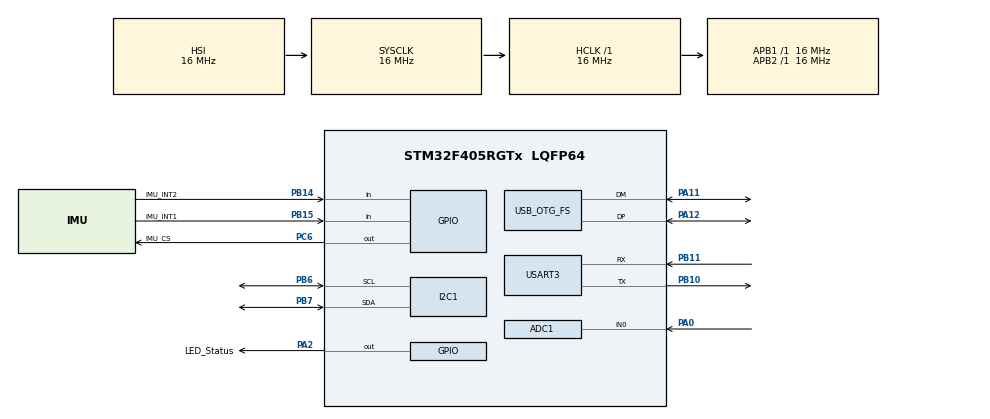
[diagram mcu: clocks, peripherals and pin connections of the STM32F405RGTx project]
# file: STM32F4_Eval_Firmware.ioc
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ADC1.Channel-0\#ChannelRegularConversion=ADC_CHANNEL_0
ADC1.NbrOfConversionFlag=1
ADC1.Rank-0\#ChannelRegularConversion=1
ADC1.SamplingTime-0\#ChannelRegularConversion=ADC_SAMPLETIME_3CYCLES
ADC1.master=1
Mcu.Family=STM32F4
Mcu.Name=STM32F405RGTx
Mcu.Package=LQFP64
NVIC.OTG_FS_IRQn=true\:0\:0\:false\:false\:true\:false\:true
NVIC.PriorityGroup=NVIC_PRIORITYGROUP_4
NVIC.TIM1_TRG_COM_TIM11_IRQn=true\:0\:0\:false\:false\:true\:true\:true
NVIC.USART3_IRQn=true\:0\:0\:false\:false\:true\:true\:true
PA0-WKUP.Signal=ADCx_IN0
PA11.Mode=Device_Only
PA11.Signal=USB_OTG_FS_DM
PA12.Mode=Device_Only
PA12.Signal=USB_OTG_FS_DP
PA13.Mode=Trace_Asynchronous_SW
PA13.Signal=SYS_JTMS-SWDIO
PA14.Mode=Trace_Asynchronous_SW
PA14.Signal=SYS_JTCK-SWCLK
PA2.GPIO_Label=LED_Status
PA2.Signal=GPIO_Output
PB10.Mode=Asynchronous
PB10.Signal=USART3_TX
PB11.Mode=Asynchronous
PB11.Signal=USART3_RX
PB14.GPIO_Label=IMU_INT2
PB14.Signal=GPIO_Input
PB15.GPIO_Label=IMU_INT1
PB15.Signal=GPIO_Input
PB3.Mode=Trace_Asynchronous_SW
PB3.Signal=SYS_JTDO-SWO
PB6.Mode=I2C
PB6.Signal=I2C1_SCL
PB7.Mode=I2C
PB7.Signal=I2C1_SDA
PC6.GPIO_Label=IMU_CS
PC6.Signal=GPIO_Output
PH0-OSC_IN.Mode=HSE-External-Oscillator
PH0-OSC_IN.Signal=RCC_OSC_IN
PH1-OSC_OUT.Mode=HSE-External-Oscillator
PH1-OSC_OUT.Signal=RCC_OSC_OUT
ProjectManager.HeapSize=0x200
ProjectManager.StackSize=0x400
ProjectManager.TargetToolchain=STM32CubeIDE
RCC.48MHZClocksFreq_Value=48000000
RCC.AHBFreq_Value=16000000
RCC.APB1Freq_Value=16000000
RCC.APB1TimFreq_Value=16000000
RCC.APB2Freq_Value=16000000
RCC.APB2TimFreq_Value=16000000
RCC.CortexFreq_Value=16000000
RCC.HCLKFreq_Value=16000000
RCC.HSE_VALUE=25000000
RCC.HSI_VALUE=16000000
RCC.LSE_VALUE=32768
RCC.PLLM=15
RCC.PLLN=144
RCC.PLLQ=5
RCC.SYSCLKFreq_VALUE=16000000
RCC.VCOOutputFreq_Value=240000000
SH.ADCx_IN0.0=ADC1_IN0,IN0
TIM11.Period=15850
TIM11.Prescaler=0
USART3.VirtualMode=VM_ASYNC
USB_DEVICE.CLASS_NAME_FS=CDC
USB_DEVICE.VirtualMode-CDC_FS=Cdc
USB_DEVICE.VirtualModeFS=Cdc_FS
USB_OTG_FS.VirtualMode=Device_Only
VP_TIM11_VS_ClockSourceINT.Mode=Enable_Timer
VP_USB_DEVICE_VS_USB_DEVICE_CDC_FS.Mode=CDC_FS
board=custom

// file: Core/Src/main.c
/* USER CODE BEGIN Header */
/**
  ******************************************************************************
  * @file           : main.c
  * @brief          : Main program body
  ******************************************************************************
  * @attention
  *
  * <h2><center>&copy; Copyright (c) 2020 STMicroelectronics.
  * All rights reserved.</center></h2>
  *
  * This software component is licensed by ST under BSD 3-Clause license,
  * the "License"; You may not use this file except in compliance with the
  * License. You may obtain a copy of the License at:
  *                        opensource.org/licenses/BSD-3-Clause
  *
  ******************************************************************************
  */
/* USER CODE END Header */
#include "main.h"
#include "usb_device.h"

ADC_HandleTypeDef hadc1;

I2C_HandleTypeDef hi2c1;

TIM_HandleTypeDef htim11;

UART_HandleTypeDef huart3;

void SystemClock_Config(void);
static void MX_GPIO_Init(void);
static void MX_I2C1_Init(void);
static void MX_USART3_UART_Init(void);
static void MX_ADC1_Init(void);
static void MX_TIM11_Init(void);
/* USER CODE BEGIN PFP */
extern void System_Init();	    //eval.c
extern void System_Control();	//eval.c	infinite loop

/* USER CODE END PFP */

int main(void)
{

  /* MCU Configuration--------------------------------------------------------*/

  /* Reset of all peripherals, Initializes the Flash interface and the Systick. */
  HAL_Init();

  /* Configure the system clock */
  SystemClock_Config();

  /* Initialize all configured peripherals */
  MX_GPIO_Init();
  MX_I2C1_Init();
  MX_USART3_UART_Init();
  MX_USB_DEVICE_Init();
  MX_ADC1_Init();
  MX_TIM11_Init();
  /* USER CODE BEGIN 2 */
  HAL_TIM_Base_Start_IT(&htim11);
  /* USER CODE END 2 */

  /* Infinite loop */
  /* USER CODE BEGIN WHILE */
  System_Init();
  System_Control();

    /* USER CODE END WHILE */

}

void SystemClock_Config(void)
{
  RCC_OscInitTypeDef RCC_OscInitStruct = {0};
  RCC_ClkInitTypeDef RCC_ClkInitStruct = {0};

  /** Configure the main internal regulator output voltage
  */
  __HAL_RCC_PWR_CLK_ENABLE();
  __HAL_PWR_VOLTAGESCALING_CONFIG(PWR_REGULATOR_VOLTAGE_SCALE1);
  /** Initializes the RCC Oscillators according to the specified parameters
  * in the RCC_OscInitTypeDef structure.
  */
  RCC_OscInitStruct.OscillatorType = RCC_OSCILLATORTYPE_HSI|RCC_OSCILLATORTYPE_HSE;
  RCC_OscInitStruct.HSEState = RCC_HSE_ON;
  RCC_OscInitStruct.HSIState = RCC_HSI_ON;
  RCC_OscInitStruct.HSICalibrationValue = RCC_HSICALIBRATION_DEFAULT;
  RCC_OscInitStruct.PLL.PLLState = RCC_PLL_ON;
  RCC_OscInitStruct.PLL.PLLSource = RCC_PLLSOURCE_HSE;
  RCC_OscInitStruct.PLL.PLLM = 15;
  RCC_OscInitStruct.PLL.PLLN = 144;
  RCC_OscInitStruct.PLL.PLLP = RCC_PLLP_DIV2;
  RCC_OscInitStruct.PLL.PLLQ = 5;
  if (HAL_RCC_OscConfig(&RCC_OscInitStruct) != HAL_OK)
  {
    Error_Handler();
  }
  /** Initializes the CPU, AHB and APB buses clocks
  */
  RCC_ClkInitStruct.ClockType = RCC_CLOCKTYPE_HCLK|RCC_CLOCKTYPE_SYSCLK
                              |RCC_CLOCKTYPE_PCLK1|RCC_CLOCKTYPE_PCLK2;
  RCC_ClkInitStruct.SYSCLKSource = RCC_SYSCLKSOURCE_HSI;
  RCC_ClkInitStruct.AHBCLKDivider = RCC_SYSCLK_DIV1;
  RCC_ClkInitStruct.APB1CLKDivider = RCC_HCLK_DIV1;
  RCC_ClkInitStruct.APB2CLKDivider = RCC_HCLK_DIV1;

  if (HAL_RCC_ClockConfig(&RCC_ClkInitStruct, FLASH_LATENCY_0) != HAL_OK)
  {
    Error_Handler();
  }
}

static void MX_ADC1_Init(void)
{

  ADC_ChannelConfTypeDef sConfig = {0};

  /** Configure the global features of the ADC (Clock, Resolution, Data Alignment and number of conversion)
  */
  hadc1.Instance = ADC1;
  hadc1.Init.ClockPrescaler = ADC_CLOCK_SYNC_PCLK_DIV2;
  hadc1.Init.Resolution = ADC_RESOLUTION_12B;
  hadc1.Init.ScanConvMode = DISABLE;
  hadc1.Init.ContinuousConvMode = DISABLE;
  hadc1.Init.DiscontinuousConvMode = DISABLE;
  hadc1.Init.ExternalTrigConvEdge = ADC_EXTERNALTRIGCONVEDGE_NONE;
  hadc1.Init.ExternalTrigConv = ADC_SOFTWARE_START;
  hadc1.Init.DataAlign = ADC_DATAALIGN_RIGHT;
  hadc1.Init.NbrOfConversion = 1;
  hadc1.Init.DMAContinuousRequests = DISABLE;
  hadc1.Init.EOCSelection = ADC_EOC_SINGLE_CONV;
  if (HAL_ADC_Init(&hadc1) != HAL_OK)
  {
    Error_Handler();
  }
  /** Configure for the selected ADC regular channel its corresponding rank in the sequencer and its sample time.
  */
  sConfig.Channel = ADC_CHANNEL_0;
  sConfig.Rank = 1;
  sConfig.SamplingTime = ADC_SAMPLETIME_3CYCLES;
  if (HAL_ADC_ConfigChannel(&hadc1, &sConfig) != HAL_OK)
  {
    Error_Handler();
  }

}

static void MX_I2C1_Init(void)
{

  hi2c1.Instance = I2C1;
  hi2c1.Init.ClockSpeed = 100000;
  hi2c1.Init.DutyCycle = I2C_DUTYCYCLE_2;
  hi2c1.Init.OwnAddress1 = 0;
  hi2c1.Init.AddressingMode = I2C_ADDRESSINGMODE_7BIT;
  hi2c1.Init.DualAddressMode = I2C_DUALADDRESS_DISABLE;
  hi2c1.Init.OwnAddress2 = 0;
  hi2c1.Init.GeneralCallMode = I2C_GENERALCALL_DISABLE;
  hi2c1.Init.NoStretchMode = I2C_NOSTRETCH_DISABLE;
  if (HAL_I2C_Init(&hi2c1) != HAL_OK)
  {
    Error_Handler();
  }

}

static void MX_TIM11_Init(void)
{

  htim11.Instance = TIM11;
  htim11.Init.Prescaler = 0;
  htim11.Init.CounterMode = TIM_COUNTERMODE_UP;
  htim11.Init.Period = 15850;
  htim11.Init.ClockDivision = TIM_CLOCKDIVISION_DIV1;
  htim11.Init.AutoReloadPreload = TIM_AUTORELOAD_PRELOAD_DISABLE;
  if (HAL_TIM_Base_Init(&htim11) != HAL_OK)
  {
    Error_Handler();
  }

}

static void MX_USART3_UART_Init(void)
{

  huart3.Instance = USART3;
  huart3.Init.BaudRate = 115200;
  huart3.Init.WordLength = UART_WORDLENGTH_8B;
  huart3.Init.StopBits = UART_STOPBITS_1;
  huart3.Init.Parity = UART_PARITY_NONE;
  huart3.Init.Mode = UART_MODE_TX_RX;
  huart3.Init.HwFlowCtl = UART_HWCONTROL_NONE;
  huart3.Init.OverSampling = UART_OVERSAMPLING_16;
  if (HAL_UART_Init(&huart3) != HAL_OK)
  {
    Error_Handler();
  }

}

static void MX_GPIO_Init(void)
{
  GPIO_InitTypeDef GPIO_InitStruct = {0};

  /* GPIO Ports Clock Enable */
  __HAL_RCC_GPIOH_CLK_ENABLE();
  __HAL_RCC_GPIOA_CLK_ENABLE();
  __HAL_RCC_GPIOB_CLK_ENABLE();
  __HAL_RCC_GPIOC_CLK_ENABLE();

  /*Configure GPIO pin Output Level */
  HAL_GPIO_WritePin(LED_Status_GPIO_Port, LED_Status_Pin, GPIO_PIN_RESET);

  /*Configure GPIO pin Output Level */
  HAL_GPIO_WritePin(IMU_CS_GPIO_Port, IMU_CS_Pin, GPIO_PIN_RESET);

  /*Configure GPIO pin : LED_Status_Pin */
  GPIO_InitStruct.Pin = LED_Status_Pin;
  GPIO_InitStruct.Mode = GPIO_MODE_OUTPUT_PP;
  GPIO_InitStruct.Pull = GPIO_NOPULL;
  GPIO_InitStruct.Speed = GPIO_SPEED_FREQ_LOW;
  HAL_GPIO_Init(LED_Status_GPIO_Port, &GPIO_InitStruct);

  /*Configure GPIO pins : IMU_INT2_Pin IMU_INT1_Pin */
  GPIO_InitStruct.Pin = IMU_INT2_Pin|IMU_INT1_Pin;
  GPIO_InitStruct.Mode = GPIO_MODE_INPUT;
  GPIO_InitStruct.Pull = GPIO_NOPULL;
  HAL_GPIO_Init(GPIOB, &GPIO_InitStruct);

  /*Configure GPIO pin : IMU_CS_Pin */
  GPIO_InitStruct.Pin = IMU_CS_Pin;
  GPIO_InitStruct.Mode = GPIO_MODE_OUTPUT_PP;
  GPIO_InitStruct.Pull = GPIO_NOPULL;
  GPIO_InitStruct.Speed = GPIO_SPEED_FREQ_LOW;
  HAL_GPIO_Init(IMU_CS_GPIO_Port, &GPIO_InitStruct);

}

void Error_Handler(void)
{
}

/************************ (C) COPYRIGHT STMicroelectronics *****END OF FILE****/
